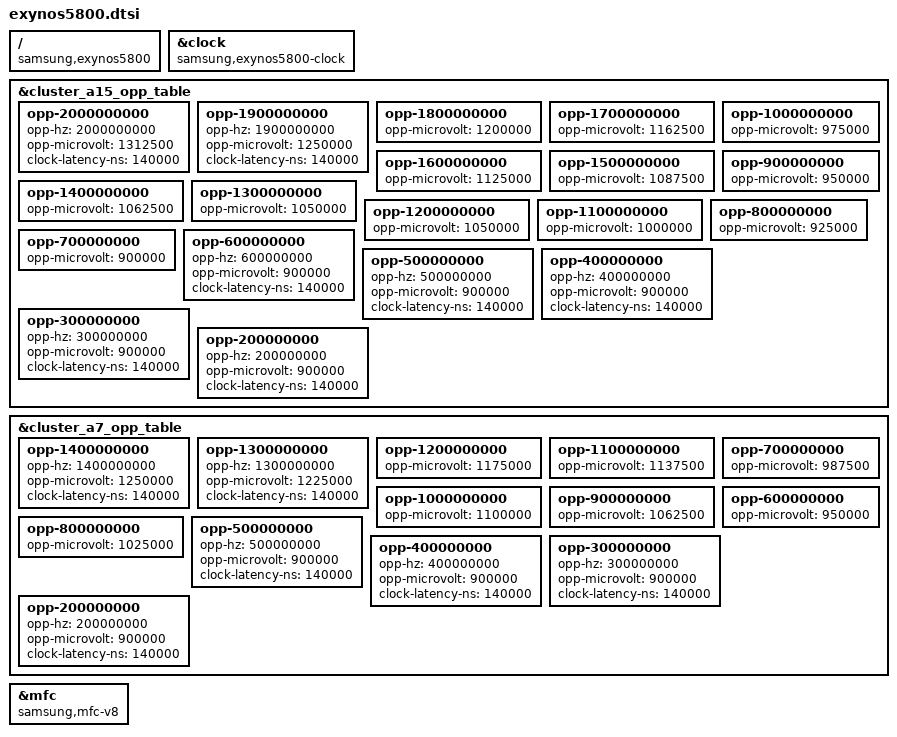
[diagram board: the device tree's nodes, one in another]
/*
 * SAMSUNG EXYNOS5800 SoC device tree source
 *
 * Copyright (c) 2014 Samsung Electronics Co., Ltd.
 *		http://www.samsung.com
 *
 * SAMSUNG EXYNOS5800 SoC device nodes are listed in this file.
 * EXYNOS5800 based board files can include this file and provide
 * values for board specfic bindings.
 *
 * This program is free software; you can redistribute it and/or modify
 * it under the terms of the GNU General Public License version 2 as
 * published by the Free Software Foundation.
 */

#include "exynos5420.dtsi"

/ {
	compatible = "samsung,exynos5800", "samsung,exynos5";
};

&clock {
	compatible = "samsung,exynos5800-clock";
};

&cluster_a15_opp_table {
	opp-2000000000 {
		opp-hz = /bits/ 64 <2000000000>;
		opp-microvolt = <1312500>;
		clock-latency-ns = <140000>;
	};
	opp-1900000000 {
		opp-hz = /bits/64 <1900000000>;
		opp-microvolt = <1250000>;
		clock-latency-ns = <140000>;
	};
	opp-1800000000 {
		opp-microvolt = <1200000>;
	};
	opp-1700000000 {
		opp-microvolt = <1162500>;
	};
	opp-1600000000 {
		opp-microvolt = <1125000>;
	};
	opp-1500000000 {
		opp-microvolt = <1087500>;
	};
	opp-1400000000 {
		opp-microvolt = <1062500>;
	};
	opp-1300000000 {
		opp-microvolt = <1050000>;
	};
	opp-1200000000 {
		opp-microvolt = <1050000>;
	};
	opp-1100000000 {
		opp-microvolt = <1000000>;
	};
	opp-1000000000 {
		opp-microvolt = <975000>;
	};
	opp-900000000 {
		opp-microvolt = <950000>;
	};
	opp-800000000 {
		opp-microvolt = <925000>;
	};
	opp-700000000 {
		opp-microvolt = <900000>;
	};
	opp-600000000 {
		opp-hz = /bits/ 64 <600000000>;
		opp-microvolt = <900000>;
		clock-latency-ns = <140000>;
	};
	opp-500000000 {
		opp-hz = /bits/ 64 <500000000>;
		opp-microvolt = <900000>;
		clock-latency-ns = <140000>;
	};
	opp-400000000 {
		opp-hz = /bits/ 64 <400000000>;
		opp-microvolt = <900000>;
		clock-latency-ns = <140000>;
	};
	opp-300000000 {
		opp-hz = /bits/ 64 <300000000>;
		opp-microvolt = <900000>;
		clock-latency-ns = <140000>;
	};
	opp-200000000 {
		opp-hz = /bits/ 64 <200000000>;
		opp-microvolt = <900000>;
		clock-latency-ns = <140000>;
	};
};

&cluster_a7_opp_table {
	opp-1400000000 {
		opp-hz = /bits/ 64 <1400000000>;
		opp-microvolt = <1250000>;
		clock-latency-ns = <140000>;
	};
	opp-1300000000 {
		opp-hz = /bits/ 64 <1300000000>;
		opp-microvolt = <1225000>;
		clock-latency-ns = <140000>;
	};
	opp-1200000000 {
		opp-microvolt = <1175000>;
	};
	opp-1100000000 {
		opp-microvolt = <1137500>;
	};
	opp-1000000000 {
		opp-microvolt = <1100000>;
	};
	opp-900000000 {
		opp-microvolt = <1062500>;
	};
	opp-800000000 {
		opp-microvolt = <1025000>;
	};
	opp-700000000 {
		opp-microvolt = <987500>;
	};
	opp-600000000 {
		opp-microvolt = <950000>;
	};
	opp-500000000 {
		opp-hz = /bits/ 64 <500000000>;
		opp-microvolt = <900000>;
		clock-latency-ns = <140000>;
	};
	opp-400000000 {
		opp-hz = /bits/ 64 <400000000>;
		opp-microvolt = <900000>;
		clock-latency-ns = <140000>;
	};
	opp-300000000 {
		opp-hz = /bits/ 64 <300000000>;
		opp-microvolt = <900000>;
		clock-latency-ns = <140000>;
	};
	opp-200000000 {
		opp-hz = /bits/ 64 <200000000>;
		opp-microvolt = <900000>;
		clock-latency-ns = <140000>;
	};
};

&mfc {
	compatible = "samsung,mfc-v8";
};
